# EFR32MG24A020F1536IM40 register map
Vendor: Silicon Labs; Series: EFR32; File version: B
Registers are 32-bit, read-write, reset 0x0 unless marked. A register's access mark holds for its fields unless they carry their own. Offsets are from the block's base; [hi:lo] are bit positions; {n}, {i} and the like mark numbered series; 'fields as' and 'values as' point back to an identical list.

## RFCRC_S — RFCRC_S Registers
Base 0xA8010000
Same registers: RFCRC_NS 0xB8010000
0x00 IPVERSION ro
0x04 EN
  [0] EN — Enable peripheral clock to this module
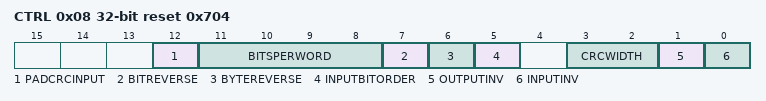
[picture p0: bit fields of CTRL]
0x08 CTRL reset 0x704
  [12] PADCRCINPUT — Pad CRC input data
    0=No zero-padding of CRC input data is applied; 1=CRC input data is zero-padded, such that the number of bytes over which the CRC value is calculated at least equals the length of the calculated CRC value
  [11:8] BITSPERWORD — Number of bits per input word
  [7] BITREVERSE — Reverse CRC bit ordering over air
    0=NORMAL (The bit ordering of CRC data is the same as defined by the BITORDER field in the Frame Controller.); 1=REVERSED (The bit ordering of CRC data is the opposite as defined by the BITORDER field in the Frame Controller.)
  [6] BYTEREVERSE — Reverse CRC byte ordering over air
    0=NORMAL (The least significant byte of the CRC register is transferred first over air via the Frame Controller.); 1=REVERSED (The most significant byte of the CRC register is transferred first over air via the Frame Controller.)
  [5] INPUTBITORDER — CRC input bit ordering setting
    0=LSBFIRST (The least significant data bit is first input to the CRC generator.); 1=MSBFIRST (The most significant data bit is first input to the CRC generator.)
  [3:2] CRCWIDTH
    0=8 bit (1 Byte) CRC code; 1=16 bit (2 Bytes) CRC code; 2=24 bit (3 Bytes) CRC code; 3=32 bit (4 Bytes) CRC code
  [1] OUTPUTINV — Output Invert
  [0] INPUTINV — Input Invert
0x0C STATUS ro
  [0] BUSY — CRC Running
0x10 CMD wo
  [0] INITIALIZE — Initialize CRC
0x14 INPUTDATA wo
  [15:0] INPUTDATA
0x18 INIT
  [31:0] INIT — CRC Initialization Value
0x1C DATA ro
  [31:0] DATA — CRC Data Register
0x20 POLY
  [31:0] POLY — CRC Polynomial Value

## ECAIFADC_S — ECAIFADC_S Registers
Base 0xA8038000
Same registers: ECAIFADC_NS 0xB8038000
0x00 IPVERSION ro reset 0x1
  [31:0] IPVERSION — IP version ID
0x04 EN
  [0] EN — IFADC Debug Enable
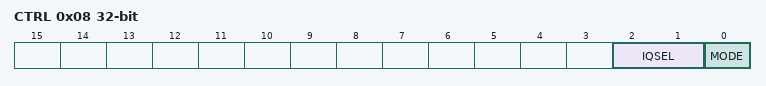
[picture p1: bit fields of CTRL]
0x08 CTRL
  [2:1] IQSEL — IQ selection
    0=NA (Not used); 1=IONLY (Only sample I values); 2=QONLY (Only sample Q values); 3=IANDQ (Sample I and Q values)
  [0] MODE
    0=MP (Magnitude + Phase +AGC); 1=IQ (I + Q + AGC)
0x10 STATUS ro
  [0] OVERFLOW — Capture Overflow

## BUFC_S — BUFC_S Registers
Base 0xAA000000
Same registers: BUFC_NS 0xBA000000
0x00 IPVERSION ro reset 0x4
0x04 EN
  [0] EN — Enable peripheral clock to this module
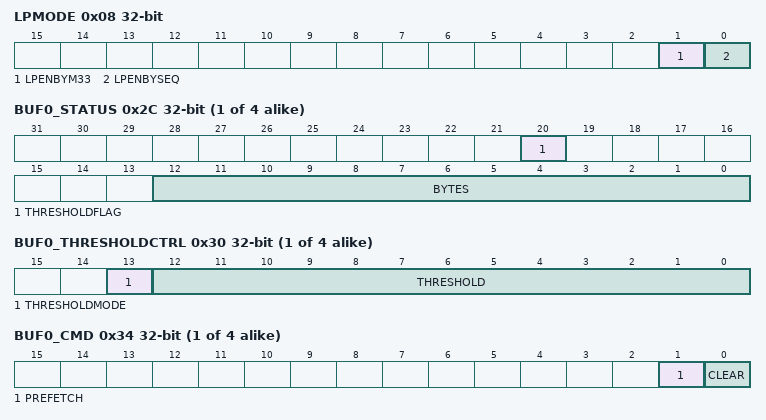
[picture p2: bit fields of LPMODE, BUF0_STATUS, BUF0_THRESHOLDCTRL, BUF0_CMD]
0x08 LPMODE
  [1] LPENBYM33 — Low power mode enable from M33
  [0] LPENBYSEQ — Low power mode enable from sequencer
{0xC+0x40*i} BUF{i}_CTRL (i=0..3)
  [2:0] SIZE — Buffer Size
    0=Sets Buffer size to 64 bytes; 1=Sets Buffer size to 128 bytes; 2=Sets Buffer size to 256 bytes; 3=Sets Buffer size to 512 bytes; 4=Sets Buffer size to 1024 bytes; 5=Sets Buffer size to 2048 bytes; 6=Sets Buffer size to 4096 bytes
{0x10+0x40*i} BUF{i}_ADDR reset 0x20000000 (i=0..3)
  [31:2] ADDR — Buffer Address
{0x14+0x40*i} BUF{i}_WRITEOFFSET (i=0..3)
  [12:0] WRITEOFFSET
{0x18+0x40*i} BUF{i}_READOFFSET (i=0..3)
  [12:0] READOFFSET
{0x20+0x40*i} BUF{i}_READDATA ro (i=0..3)
  [7:0] READDATA — Buffer Read Data
{0x24+0x40*i} BUF{i}_WRITEDATA wo (i=0..3)
  [7:0] WRITEDATA — Buffer Write Data
{0x28+0x40*i} BUF{i}_XWRITE wo (i=0..3)
  [7:0] XORWRITEDATA — Buffer XOR Write Data
{0x2C+0x40*i} BUF{i}_STATUS ro (i=0..3)
  [20] THRESHOLDFLAG — Buffer Threshold Flag
  [12:0] BYTES — Number of Bytes in the Buffer
{0x30+0x40*i} BUF{i}_THRESHOLDCTRL (i=0..3)
  [13] THRESHOLDMODE — Buffer Threshold Mode
    0=LARGER (THRESHOLDIF will be set if BYTES is larger than THRESHOLD); 1=LESSOREQUAL (THRESHOLDIF will be set if BYTES is less than or equal to THRESHOLD)
  [12:0] THRESHOLD — Buffer Threshold Value
{0x34+0x40*i} BUF{i}_CMD wo (i=0..3)
  [1] PREFETCH
  [0] CLEAR — Buffer Clear
{0x38+0x40*i} BUF{i}_FIFOASYNC wo (i=0..3)
  [0] RST — Reset ASYNC
{0x3C+0x40*i} BUF{i}_READDATA32 ro (i=0..3)
  [31:0] READDATA32 — Buffer Read Data
{0x40+0x40*i} BUF{i}_WRITEDATA32 wo (i=0..3)
  [31:0] WRITEDATA32 — Buffer Write Data
{0x44+0x40*i} BUF{i}_XWRITE32 wo (i=0..3)
  [31:0] XORWRITEDATA32 — Buffer XOR Write Data
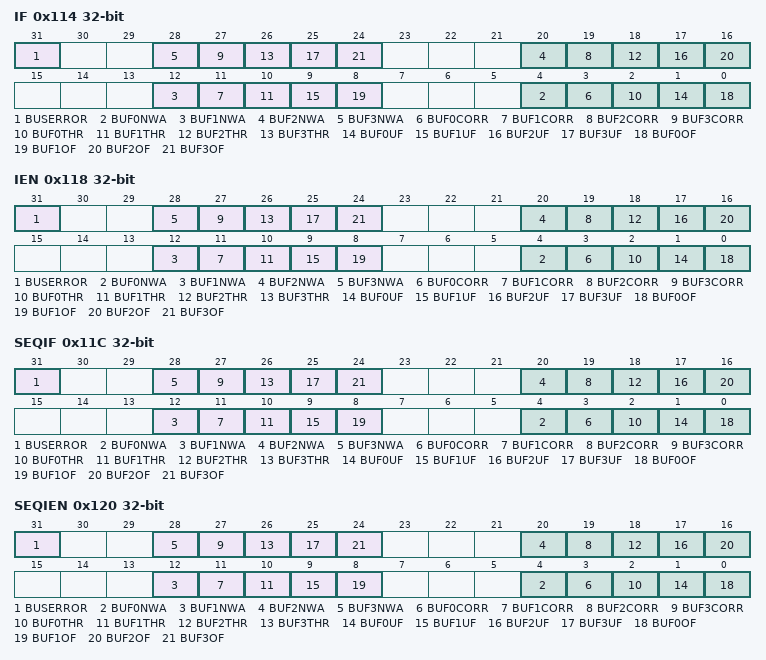
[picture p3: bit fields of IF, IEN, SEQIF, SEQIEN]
0x114 IF
  [31] BUSERROR
  [8n+4] BUF{n}NWA (n=0..3) — Buffer {n} Not Word-Aligned
  [8n+3] BUF{n}CORR (n=0..3) — Buffer {n} Corrupt
  [8n+2] BUF{n}THR (n=0..3) — Buffer {n} Threshold Event
  [8n+1] BUF{n}UF (n=0..3) — Buffer {n} Underflow
  [8n] BUF{n}OF (n=0..3) — Buffer {n} Overflow
0x118 IEN
  [31] BUSERROR — BUSERROR Interrupt Enable
  [8n+4] BUF{n}NWA (n=0..3) — BUF{n}NWA Interrupt Enable
  [8n+3] BUF{n}CORR (n=0..3) — BUF{n}CORR Interrupt Enable
  [8n+2] BUF{n}THR (n=0..3) — BUF{n}THR Interrupt Enable
  [8n+1] BUF{n}UF (n=0..3) — BUF{n}UF Interrupt Enable
  [8n] BUF{n}OF (n=0..3) — BUF{n}OF Interrupt Enable
0x11C SEQIF
  fields as IF
0x120 SEQIEN
  fields as IEN
0x124 AHBCONFIG reset 0x1
  [0] AHBHPROTBUFFERABLE — Bufferable privileged AHB
